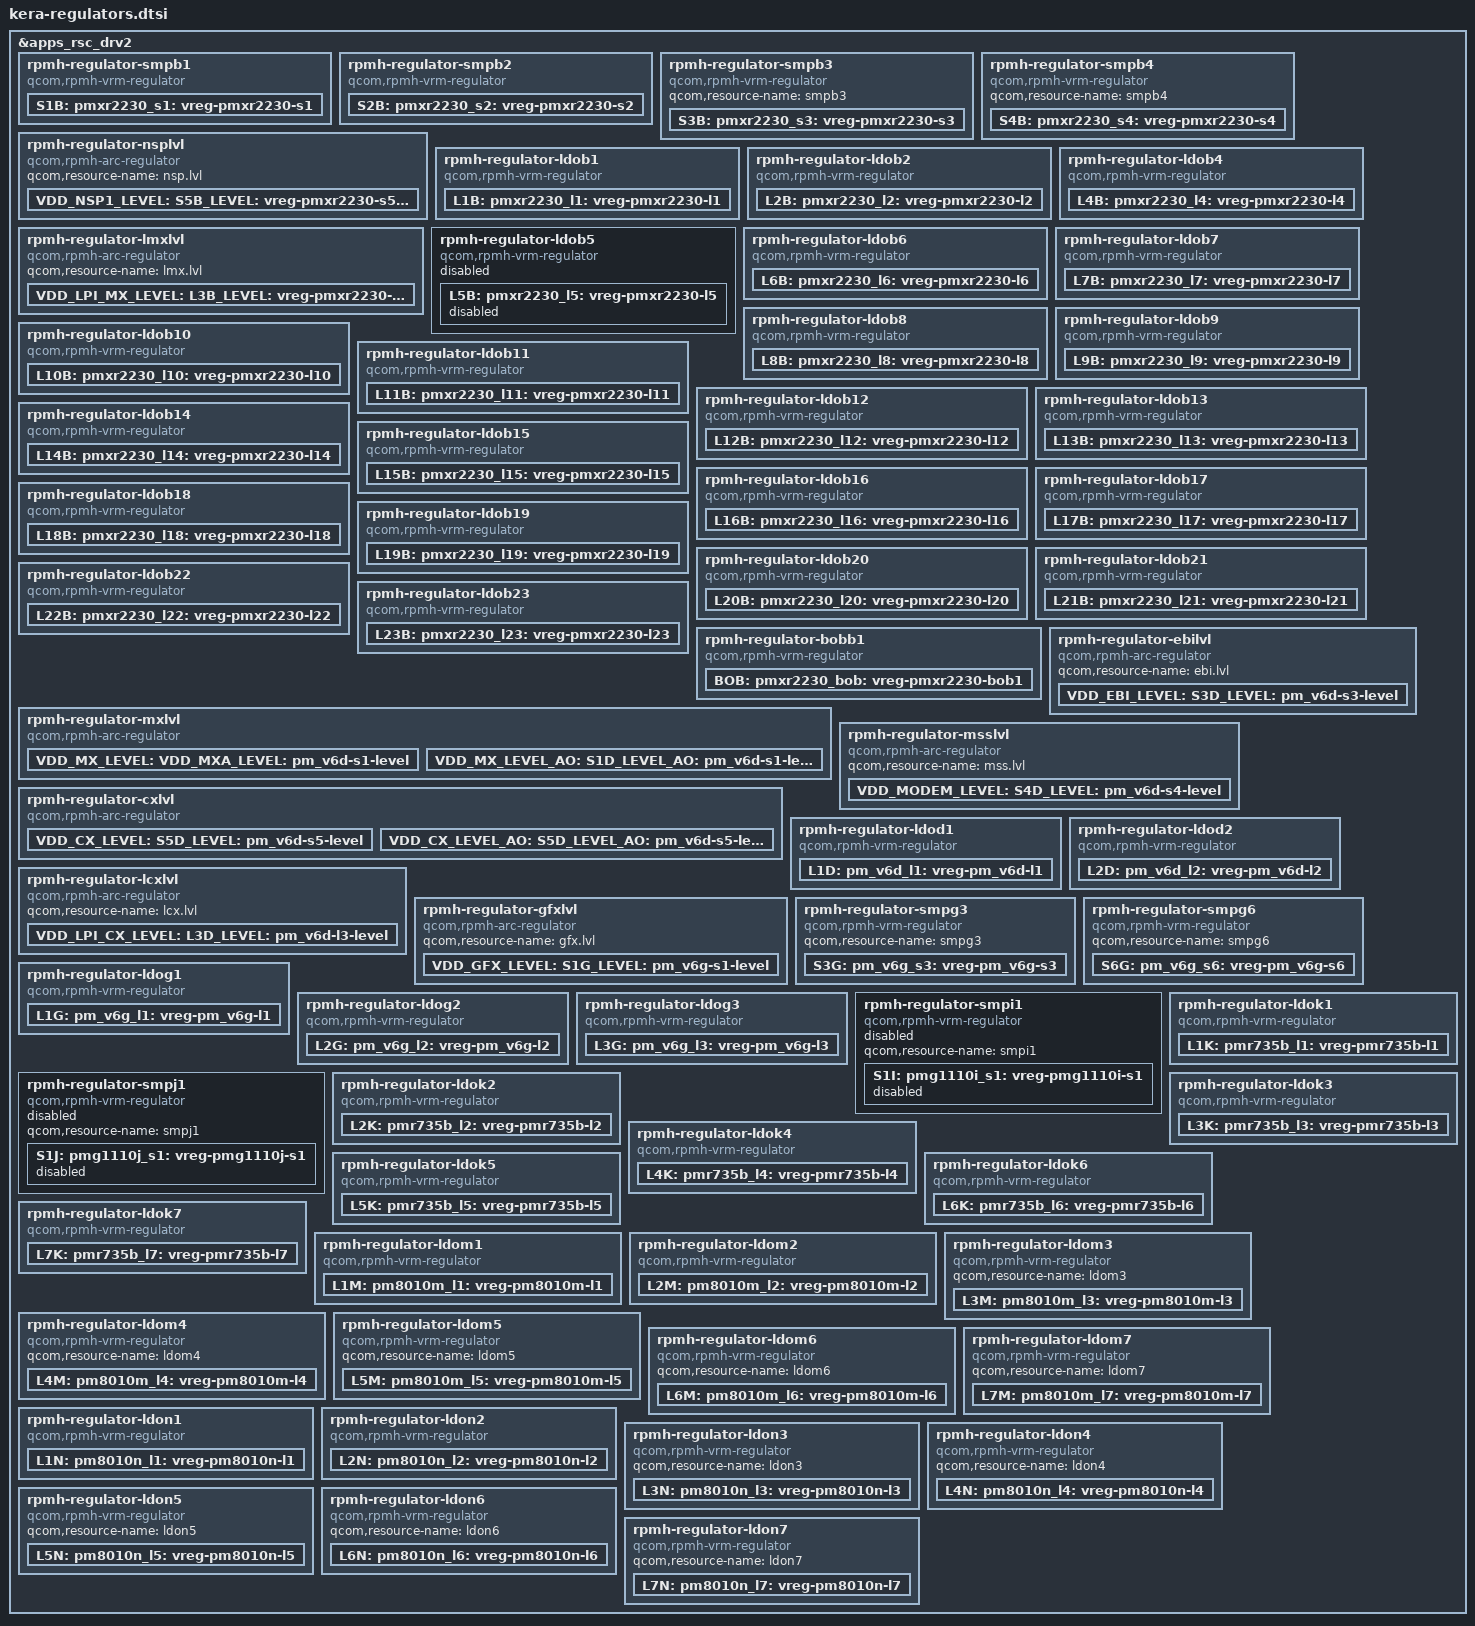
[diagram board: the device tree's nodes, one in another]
// SPDX-License-Identifier: BSD-3-Clause
/*
 * Copyright (c) 2024-2025, Qualcomm Innovation Center, Inc. All rights reserved.
 */

#include <dt-bindings/regulator/qcom,rpmh-regulator-levels.h>

&apps_rsc_drv2 {
	rpmh-regulator-smpb1 {
		compatible = "qcom,rpmh-vrm-regulator";
		qcom,resource-name = "smpb1";
		qcom,regulator-type = "pmic5-ftsmps";
		qcom,supported-modes = <RPMH_REGULATOR_MODE_RET
					RPMH_REGULATOR_MODE_HPM>;
		qcom,mode-threshold-currents = <0 200000>;

		S1B: pmxr2230_s1: vreg-pmxr2230-s1 {
			regulator-name = "pmxr2230_s1";
			qcom,set = <RPMH_REGULATOR_SET_ALL>;
			regulator-min-microvolt = <1856000>;
			regulator-max-microvolt = <2040000>;
			qcom,init-voltage = <1856000>;
			qcom,init-mode = <RPMH_REGULATOR_MODE_HPM>;
		};
	};

	rpmh-regulator-smpb2 {
		compatible = "qcom,rpmh-vrm-regulator";
		qcom,resource-name = "smpb2";
		qcom,regulator-type = "pmic5-ftsmps";
		qcom,supported-modes = <RPMH_REGULATOR_MODE_RET
					RPMH_REGULATOR_MODE_HPM>;
		qcom,mode-threshold-currents = <0 200000>;

		S2B: pmxr2230_s2: vreg-pmxr2230-s2 {
			regulator-name = "pmxr2230_s2";
			qcom,set = <RPMH_REGULATOR_SET_ALL>;
			regulator-min-microvolt = <1256000>;
			regulator-max-microvolt = <1408000>;
			qcom,init-voltage = <1256000>;
			qcom,init-mode = <RPMH_REGULATOR_MODE_HPM>;
		};
	};

	rpmh-regulator-smpb3 {
		compatible = "qcom,rpmh-vrm-regulator";
		qcom,resource-name = "smpb3";

		S3B: pmxr2230_s3: vreg-pmxr2230-s3 {
			regulator-name = "pmxr2230_s3";
			qcom,set = <RPMH_REGULATOR_SET_ALL>;
			regulator-min-microvolt = <880000>;
			regulator-max-microvolt = <1040000>;
			qcom,init-voltage = <952000>;
		};
	};

	rpmh-regulator-smpb4 {
		compatible = "qcom,rpmh-vrm-regulator";
		qcom,resource-name = "smpb4";

		S4B: pmxr2230_s4: vreg-pmxr2230-s4 {
			regulator-name = "pmxr2230_s4";
			qcom,set = <RPMH_REGULATOR_SET_ALL>;
			regulator-min-microvolt = <2156000>;
			regulator-max-microvolt = <2600000>;
			qcom,init-voltage = <2156000>;
		};
	};

	rpmh-regulator-nsplvl {
		compatible = "qcom,rpmh-arc-regulator";
		qcom,resource-name = "nsp.lvl";

		VDD_NSP1_LEVEL:
		S5B_LEVEL:
		pmxr2230_s5_level: vreg-pmxr2230-s5-level {
			regulator-name = "pmxr2230_s5_level";
			qcom,set = <RPMH_REGULATOR_SET_ALL>;
			regulator-min-microvolt =
				<RPMH_REGULATOR_LEVEL_RETENTION>;
			regulator-max-microvolt = <RPMH_REGULATOR_LEVEL_MAX>;
			qcom,init-voltage-level =
				<RPMH_REGULATOR_LEVEL_RETENTION>;
		};
	};

	rpmh-regulator-ldob1 {
		compatible = "qcom,rpmh-vrm-regulator";
		qcom,resource-name = "ldob1";
		qcom,regulator-type = "pmic5-ldo";
		qcom,supported-modes =
			<RPMH_REGULATOR_MODE_LPM
			RPMH_REGULATOR_MODE_HPM>;
		qcom,mode-threshold-currents = <0 30000>;

		L1B: pmxr2230_l1: vreg-pmxr2230-l1 {
			regulator-name = "pmxr2230_l1";
			qcom,set = <RPMH_REGULATOR_SET_ALL>;
			regulator-min-microvolt = <870000>;
			regulator-max-microvolt = <970000>;
			qcom,init-voltage = <904000>;
			qcom,init-mode = <RPMH_REGULATOR_MODE_HPM>;
		};
	};

	rpmh-regulator-ldob2 {
		compatible = "qcom,rpmh-vrm-regulator";
		qcom,resource-name = "ldob2";
		qcom,regulator-type = "pmic5-ldo";
		qcom,supported-modes =
			<RPMH_REGULATOR_MODE_LPM
			RPMH_REGULATOR_MODE_HPM>;
		qcom,mode-threshold-currents = <0 30000>;
		proxy-supply = <&L2B>;

		L2B: pmxr2230_l2: vreg-pmxr2230-l2 {
			regulator-name = "pmxr2230_l2";
			qcom,set = <RPMH_REGULATOR_SET_ALL>;
			regulator-min-microvolt = <720000>;
			regulator-max-microvolt = <950000>;
			qcom,init-voltage = <720000>;
			qcom,init-mode = <RPMH_REGULATOR_MODE_HPM>;
			qcom,proxy-consumer-enable;
			qcom,proxy-consumer-current = <98000>;
		};
	};

	rpmh-regulator-lmxlvl {
		compatible = "qcom,rpmh-arc-regulator";
		qcom,resource-name = "lmx.lvl";

		VDD_LPI_MX_LEVEL:
		L3B_LEVEL:
		pmxr2230_l3_level: vreg-pmxr2230-l3-level {
			regulator-name = "pmxr2230_l3_level";
			qcom,set = <RPMH_REGULATOR_SET_ALL>;
			regulator-min-microvolt =
				<RPMH_REGULATOR_LEVEL_RETENTION>;
			regulator-max-microvolt = <RPMH_REGULATOR_LEVEL_MAX>;
			qcom,init-voltage-level =
				<RPMH_REGULATOR_LEVEL_RETENTION>;
		};
	};

	rpmh-regulator-ldob4 {
		compatible = "qcom,rpmh-vrm-regulator";
		qcom,resource-name = "ldob4";
		qcom,regulator-type = "pmic5-ldo";
		qcom,supported-modes =
			<RPMH_REGULATOR_MODE_LPM
			RPMH_REGULATOR_MODE_HPM>;
		qcom,mode-threshold-currents = <0 30000>;
		proxy-supply = <&L4B>;

		L4B: pmxr2230_l4: vreg-pmxr2230-l4 {
			regulator-name = "pmxr2230_l4";
			qcom,set = <RPMH_REGULATOR_SET_ALL>;
			regulator-min-microvolt = <1080000>;
			regulator-max-microvolt = <1320000>;
			qcom,init-voltage = <1200000>;
			qcom,init-mode = <RPMH_REGULATOR_MODE_HPM>;
			qcom,proxy-consumer-enable;
			qcom,proxy-consumer-current = <16600>;
		};
	};

	rpmh-regulator-ldob5 {
		compatible = "qcom,rpmh-vrm-regulator";
		qcom,resource-name = "ldob5";
		qcom,regulator-type = "pmic5-ldo";
		qcom,supported-modes =
			<RPMH_REGULATOR_MODE_LPM
			RPMH_REGULATOR_MODE_HPM>;
		qcom,mode-threshold-currents = <0 30000>;
		status = "disabled";

		L5B: pmxr2230_l5: vreg-pmxr2230-l5 {
			regulator-name = "pmxr2230_l5";
			qcom,set = <RPMH_REGULATOR_SET_ALL>;
			regulator-min-microvolt = <1170000>;
			regulator-max-microvolt = <1370000>;
			qcom,init-voltage = <1200000>;
			qcom,init-mode = <RPMH_REGULATOR_MODE_HPM>;
			status = "disabled";
		};
	};

	rpmh-regulator-ldob6 {
		compatible = "qcom,rpmh-vrm-regulator";
		qcom,resource-name = "ldob6";
		qcom,regulator-type = "pmic5-ldo";
		qcom,supported-modes =
			<RPMH_REGULATOR_MODE_LPM
			RPMH_REGULATOR_MODE_HPM>;
		qcom,mode-threshold-currents = <0 30000>;

		L6B: pmxr2230_l6: vreg-pmxr2230-l6 {
			regulator-name = "pmxr2230_l6";
			qcom,set = <RPMH_REGULATOR_SET_ALL>;
			regulator-min-microvolt = <866000>;
			regulator-max-microvolt = <958000>;
			qcom,init-voltage = <912000>;
			qcom,init-mode = <RPMH_REGULATOR_MODE_HPM>;
		};
	};

	rpmh-regulator-ldob7 {
		compatible = "qcom,rpmh-vrm-regulator";
		qcom,resource-name = "ldob7";
		qcom,regulator-type = "pmic5-ldo";
		qcom,supported-modes =
			<RPMH_REGULATOR_MODE_LPM
			RPMH_REGULATOR_MODE_HPM>;
		qcom,mode-threshold-currents = <0 30000>;

		L7B: pmxr2230_l7: vreg-pmxr2230-l7 {
			regulator-name = "pmxr2230_l7";
			qcom,set = <RPMH_REGULATOR_SET_ALL>;
			regulator-min-microvolt = <1800000>;
			regulator-max-microvolt = <2000000>;
			qcom,init-voltage = <1800000>;
			qcom,init-mode = <RPMH_REGULATOR_MODE_HPM>;
		};
	};

	rpmh-regulator-ldob8 {
		compatible = "qcom,rpmh-vrm-regulator";
		qcom,resource-name = "ldob8";
		qcom,regulator-type = "pmic5-ldo";
		qcom,supported-modes =
			<RPMH_REGULATOR_MODE_LPM
			RPMH_REGULATOR_MODE_HPM>;
		qcom,mode-threshold-currents = <0 30000>;
		proxy-supply = <&L8B>;

		L8B: pmxr2230_l8: vreg-pmxr2230-l8 {
			regulator-name = "pmxr2230_l8";
			qcom,set = <RPMH_REGULATOR_SET_ALL>;
			regulator-min-microvolt = <1650000>;
			regulator-max-microvolt = <2000000>;
			qcom,init-voltage = <1800000>;
			qcom,init-mode = <RPMH_REGULATOR_MODE_HPM>;
			qcom,proxy-consumer-enable;
			qcom,proxy-consumer-current = <154000>;
		};
	};

	rpmh-regulator-ldob9 {
		compatible = "qcom,rpmh-vrm-regulator";
		qcom,resource-name = "ldob9";
		qcom,regulator-type = "pmic5-ldo";
		qcom,supported-modes =
			<RPMH_REGULATOR_MODE_LPM
			RPMH_REGULATOR_MODE_HPM>;
		qcom,mode-threshold-currents = <0 30000>;

		L9B: pmxr2230_l9: vreg-pmxr2230-l9 {
			regulator-name = "pmxr2230_l9";
			qcom,set = <RPMH_REGULATOR_SET_ALL>;
			regulator-min-microvolt = <756000>;
			regulator-max-microvolt = <816000>;
			qcom,init-voltage = <756000>;
			qcom,init-mode = <RPMH_REGULATOR_MODE_HPM>;
		};
	};

	rpmh-regulator-ldob10 {
		compatible = "qcom,rpmh-vrm-regulator";
		qcom,resource-name = "ldob10";
		qcom,regulator-type = "pmic5-ldo";
		qcom,supported-modes =
			<RPMH_REGULATOR_MODE_LPM
			RPMH_REGULATOR_MODE_HPM>;
		qcom,mode-threshold-currents = <0 30000>;

		L10B: pmxr2230_l10: vreg-pmxr2230-l10 {
			regulator-name = "pmxr2230_l10";
			qcom,set = <RPMH_REGULATOR_SET_ALL>;
			regulator-min-microvolt = <866000>;
			regulator-max-microvolt = <958000>;
			qcom,init-voltage = <866000>;
			qcom,init-mode = <RPMH_REGULATOR_MODE_HPM>;
		};
	};

	rpmh-regulator-ldob11 {
		compatible = "qcom,rpmh-vrm-regulator";
		qcom,resource-name = "ldob11";
		qcom,regulator-type = "pmic5-ldo";
		qcom,supported-modes =
			<RPMH_REGULATOR_MODE_RET
			RPMH_REGULATOR_MODE_HPM>;
		qcom,mode-threshold-currents = <0 30000>;

		L11B: pmxr2230_l11: vreg-pmxr2230-l11 {
			regulator-name = "pmxr2230_l11";
			qcom,set = <RPMH_REGULATOR_SET_ALL>;
			regulator-min-microvolt = <1800000>;
			regulator-max-microvolt = <2000000>;
			qcom,init-voltage = <1800000>;
			qcom,init-mode = <RPMH_REGULATOR_MODE_LPM>;
			regulator-always-on;
		};
	};

	rpmh-regulator-ldob12 {
		compatible = "qcom,rpmh-vrm-regulator";
		qcom,resource-name = "ldob12";
		qcom,regulator-type = "pmic5-ldo";
		qcom,supported-modes =
			<RPMH_REGULATOR_MODE_LPM
			RPMH_REGULATOR_MODE_HPM>;
		qcom,mode-threshold-currents = <0 10000>;

		L12B: pmxr2230_l12: vreg-pmxr2230-l12 {
			regulator-name = "pmxr2230_l12";
			qcom,set = <RPMH_REGULATOR_SET_ALL>;
			qcom,init-mode = <RPMH_REGULATOR_MODE_HPM>;
		};
	};

	rpmh-regulator-ldob13 {
		compatible = "qcom,rpmh-vrm-regulator";
		qcom,resource-name = "ldob13";
		qcom,regulator-type = "pmic5-ldo";
		qcom,supported-modes =
			<RPMH_REGULATOR_MODE_LPM
			RPMH_REGULATOR_MODE_HPM>;
		qcom,mode-threshold-currents = <0 10000>;

		L13B: pmxr2230_l13: vreg-pmxr2230-l13 {
			regulator-name = "pmxr2230_l13";
			qcom,set = <RPMH_REGULATOR_SET_ALL>;
			regulator-min-microvolt = <2700000>;
			regulator-max-microvolt = <3300000>;
			qcom,init-voltage = <2700000>;
			qcom,init-mode = <RPMH_REGULATOR_MODE_HPM>;
		};
	};

	rpmh-regulator-ldob14 {
		compatible = "qcom,rpmh-vrm-regulator";
		qcom,resource-name = "ldob14";
		qcom,regulator-type = "pmic5-ldo";
		qcom,supported-modes =
			<RPMH_REGULATOR_MODE_LPM
			RPMH_REGULATOR_MODE_HPM>;
		qcom,mode-threshold-currents = <0 10000>;

		L14B: pmxr2230_l14: vreg-pmxr2230-l14 {
			regulator-name = "pmxr2230_l14";
			qcom,set = <RPMH_REGULATOR_SET_ALL>;
			regulator-min-microvolt = <2650000>;
			regulator-max-microvolt = <2940000>;
			qcom,init-voltage = <2650000>;
			qcom,init-mode = <RPMH_REGULATOR_MODE_HPM>;
		};
	};

	rpmh-regulator-ldob15 {
		compatible = "qcom,rpmh-vrm-regulator";
		qcom,resource-name = "ldob15";
		qcom,regulator-type = "pmic5-ldo";
		qcom,supported-modes =
			<RPMH_REGULATOR_MODE_LPM
			RPMH_REGULATOR_MODE_HPM>;
		qcom,mode-threshold-currents = <0 10000>;

		L15B: pmxr2230_l15: vreg-pmxr2230-l15 {
			regulator-name = "pmxr2230_l15";
			qcom,set = <RPMH_REGULATOR_SET_ALL>;
			regulator-min-microvolt = <1620000>;
			regulator-max-microvolt = <3300000>;
			qcom,init-voltage = <1620000>;
			qcom,init-mode = <RPMH_REGULATOR_MODE_HPM>;
		};
	};

	rpmh-regulator-ldob16 {
		compatible = "qcom,rpmh-vrm-regulator";
		qcom,resource-name = "ldob16";
		qcom,regulator-type = "pmic5-ldo";
		qcom,supported-modes =
			<RPMH_REGULATOR_MODE_LPM
			RPMH_REGULATOR_MODE_HPM>;
		qcom,mode-threshold-currents = <0 10000>;

		L16B: pmxr2230_l16: vreg-pmxr2230-l16 {
			regulator-name = "pmxr2230_l16";
			qcom,set = <RPMH_REGULATOR_SET_ALL>;
			regulator-min-microvolt = <2900000>;
			regulator-max-microvolt = <3544000>;
			qcom,init-voltage = <2900000>;
			qcom,init-mode = <RPMH_REGULATOR_MODE_HPM>;
		};
	};

	rpmh-regulator-ldob17 {
		compatible = "qcom,rpmh-vrm-regulator";
		qcom,resource-name = "ldob17";
		qcom,regulator-type = "pmic5-ldo";
		qcom,supported-modes =
			<RPMH_REGULATOR_MODE_LPM
			RPMH_REGULATOR_MODE_HPM>;
		qcom,mode-threshold-currents = <0 10000>;

		L17B: pmxr2230_l17: vreg-pmxr2230-l17 {
			regulator-name = "pmxr2230_l17";
			qcom,set = <RPMH_REGULATOR_SET_ALL>;
			regulator-min-microvolt = <2700000>;
			regulator-max-microvolt = <3544000>;
			qcom,init-voltage = <3104000>;
			qcom,init-mode = <RPMH_REGULATOR_MODE_HPM>;
		};
	};

	rpmh-regulator-ldob18 {
		compatible = "qcom,rpmh-vrm-regulator";
		qcom,resource-name = "ldob18";
		qcom,regulator-type = "pmic5-ldo";
		qcom,supported-modes =
			<RPMH_REGULATOR_MODE_LPM
			RPMH_REGULATOR_MODE_HPM>;
		qcom,mode-threshold-currents = <0 10000>;

		L18B: pmxr2230_l18: vreg-pmxr2230-l18 {
			regulator-name = "pmxr2230_l18";
			qcom,set = <RPMH_REGULATOR_SET_ALL>;
			regulator-min-microvolt = <1600000>;
			regulator-max-microvolt = <3544000>;
			qcom,init-voltage = <1600000>;
			qcom,init-mode = <RPMH_REGULATOR_MODE_HPM>;
		};
	};

	rpmh-regulator-ldob19 {
		compatible = "qcom,rpmh-vrm-regulator";
		qcom,resource-name = "ldob19";
		qcom,regulator-type = "pmic5-ldo";
		qcom,supported-modes =
			<RPMH_REGULATOR_MODE_LPM
			RPMH_REGULATOR_MODE_HPM>;
		qcom,mode-threshold-currents = <0 10000>;
		proxy-supply = <&L19B>;

		L19B: pmxr2230_l19: vreg-pmxr2230-l19 {
			regulator-name = "pmxr2230_l19";
			qcom,set = <RPMH_REGULATOR_SET_ALL>;
			regulator-min-microvolt = <2600000>;
			regulator-max-microvolt = <3544000>;
			qcom,init-voltage = <2600000>;
			qcom,init-mode = <RPMH_REGULATOR_MODE_HPM>;
			qcom,proxy-consumer-enable;
			qcom,proxy-consumer-current = <10000>;
		};
	};

	rpmh-regulator-ldob20 {
		compatible = "qcom,rpmh-vrm-regulator";
		qcom,resource-name = "ldob20";
		qcom,regulator-type = "pmic5-ldo";
		qcom,supported-modes =
			<RPMH_REGULATOR_MODE_LPM
			RPMH_REGULATOR_MODE_HPM>;
		qcom,mode-threshold-currents = <0 10000>;

		L20B: pmxr2230_l20: vreg-pmxr2230-l20 {
			regulator-name = "pmxr2230_l20";
			qcom,set = <RPMH_REGULATOR_SET_ALL>;
			regulator-min-microvolt = <1504000>;
			regulator-max-microvolt = <3544000>;
			qcom,init-voltage = <1504000>;
			qcom,init-mode = <RPMH_REGULATOR_MODE_HPM>;
		};
	};

	rpmh-regulator-ldob21 {
		compatible = "qcom,rpmh-vrm-regulator";
		qcom,resource-name = "ldob21";
		qcom,regulator-type = "pmic5-ldo";
		qcom,supported-modes =
			<RPMH_REGULATOR_MODE_LPM
			RPMH_REGULATOR_MODE_HPM>;
		qcom,mode-threshold-currents = <0 10000>;

		L21B: pmxr2230_l21: vreg-pmxr2230-l21 {
			regulator-name = "pmxr2230_l21";
			qcom,set = <RPMH_REGULATOR_SET_ALL>;
			regulator-min-microvolt = <1504000>;
			regulator-max-microvolt = <3544000>;
			qcom,init-voltage = <1504000>;
			qcom,init-mode = <RPMH_REGULATOR_MODE_HPM>;
		};
	};

	rpmh-regulator-ldob22 {
		compatible = "qcom,rpmh-vrm-regulator";
		qcom,resource-name = "ldob22";
		qcom,regulator-type = "pmic5-ldo";
		qcom,supported-modes =
			<RPMH_REGULATOR_MODE_LPM
			RPMH_REGULATOR_MODE_HPM>;
		qcom,mode-threshold-currents = <0 10000>;

		L22B: pmxr2230_l22: vreg-pmxr2230-l22 {
			regulator-name = "pmxr2230_l22";
			qcom,set = <RPMH_REGULATOR_SET_ALL>;
			regulator-min-microvolt = <2700000>;
			regulator-max-microvolt = <3400000>;
			qcom,init-voltage = <2700000>;
			qcom,init-mode = <RPMH_REGULATOR_MODE_HPM>;
		};
	};

	rpmh-regulator-ldob23 {
		compatible = "qcom,rpmh-vrm-regulator";
		qcom,resource-name = "ldob23";
		qcom,regulator-type = "pmic5-ldo";
		qcom,supported-modes =
			<RPMH_REGULATOR_MODE_LPM
			RPMH_REGULATOR_MODE_HPM>;
		qcom,mode-threshold-currents = <0 10000>;

		L23B: pmxr2230_l23: vreg-pmxr2230-l23 {
			regulator-name = "pmxr2230_l23";
			qcom,set = <RPMH_REGULATOR_SET_ALL>;
			regulator-min-microvolt = <1650000>;
			regulator-max-microvolt = <3544000>;
			qcom,init-voltage = <1650000>;
			qcom,init-mode = <RPMH_REGULATOR_MODE_HPM>;
		};
	};

	rpmh-regulator-bobb1 {
		compatible = "qcom,rpmh-vrm-regulator";
		qcom,resource-name = "bobb1";
		qcom,regulator-type = "pmic5-bob";
		qcom,supported-modes =
			<RPMH_REGULATOR_MODE_PASS
			RPMH_REGULATOR_MODE_LPM
			RPMH_REGULATOR_MODE_HPM>;
		qcom,mode-threshold-currents = <0 1000000 2000000>;
		BOB:
		pmxr2230_bob: vreg-pmxr2230-bob1 {
			regulator-name = "pmxr2230_bob";
			qcom,set = <RPMH_REGULATOR_SET_ALL>;
			regulator-min-microvolt = <3008000>;
			regulator-max-microvolt = <3960000>;
			qcom,init-voltage = <3296000>;
		};
	};

	rpmh-regulator-mxlvl {
		compatible = "qcom,rpmh-arc-regulator";
		qcom,resource-name = "mx.lvl";
		proxy-supply = <&VDD_MXA_LEVEL>;

		VDD_MX_LEVEL:
		VDD_MXA_LEVEL:
		S1D_LEVEL:
		pm_v6d_s1_level: pm_v6d-s1-level {
			regulator-name = "pm_v6d_s1_level";
			qcom,set = <RPMH_REGULATOR_SET_ALL>;
			regulator-min-microvolt =
				<RPMH_REGULATOR_LEVEL_RETENTION>;
			regulator-max-microvolt = <RPMH_REGULATOR_LEVEL_MAX>;
			qcom,init-voltage-level =
				<RPMH_REGULATOR_LEVEL_TURBO>;
			qcom,proxy-consumer-enable;
			qcom,proxy-consumer-voltage =
				<RPMH_REGULATOR_LEVEL_TURBO
				RPMH_REGULATOR_LEVEL_MAX>;
		};

		VDD_MX_LEVEL_AO:
		S1D_LEVEL_AO:
		pm_v6d_s1_level_ao: pm_v6d-s1-level-ao {
			regulator-name = "pm_v6d_s1_level_ao";
			qcom,set = <RPMH_REGULATOR_SET_ACTIVE>;
			regulator-min-microvolt =
				<RPMH_REGULATOR_LEVEL_RETENTION>;
			regulator-max-microvolt = <RPMH_REGULATOR_LEVEL_MAX>;
			qcom,init-voltage-level =
				<RPMH_REGULATOR_LEVEL_RETENTION>;
		};
	};

	rpmh-regulator-ebilvl {
		compatible = "qcom,rpmh-arc-regulator";
		qcom,resource-name = "ebi.lvl";

		VDD_EBI_LEVEL:
		S3D_LEVEL:
		pm_v6d_s3_level: pm_v6d-s3-level {
			regulator-name = "pm_v6d_s3_level";
			qcom,set = <RPMH_REGULATOR_SET_ALL>;
			regulator-min-microvolt =
				<RPMH_REGULATOR_LEVEL_RETENTION>;
			regulator-max-microvolt = <RPMH_REGULATOR_LEVEL_MAX>;
			qcom,init-voltage-level =
				<RPMH_REGULATOR_LEVEL_RETENTION>;
		};
	};

	rpmh-regulator-msslvl {
		compatible = "qcom,rpmh-arc-regulator";
		qcom,resource-name = "mss.lvl";

		VDD_MODEM_LEVEL:
		S4D_LEVEL:
		pm_v6d_s4_level: pm_v6d-s4-level {
			regulator-name = "pm_v6d_s4_level";
			qcom,set = <RPMH_REGULATOR_SET_ALL>;
			regulator-min-microvolt =
				<RPMH_REGULATOR_LEVEL_RETENTION>;
			regulator-max-microvolt = <RPMH_REGULATOR_LEVEL_MAX>;
			qcom,init-voltage-level =
				<RPMH_REGULATOR_LEVEL_RETENTION>;
		};
	};

	rpmh-regulator-cxlvl {
		compatible = "qcom,rpmh-arc-regulator";
		qcom,resource-name = "cx.lvl";
		proxy-supply = <&VDD_CX_LEVEL>;

		VDD_CX_LEVEL:
		S5D_LEVEL:
		pm_v6d_s5_level: pm_v6d-s5-level {
			regulator-name = "pm_v6d_s5_level";
			qcom,set = <RPMH_REGULATOR_SET_ALL>;
			regulator-min-microvolt =
				<RPMH_REGULATOR_LEVEL_RETENTION>;
			regulator-max-microvolt = <RPMH_REGULATOR_LEVEL_MAX>;
			qcom,init-voltage-level =
				<RPMH_REGULATOR_LEVEL_TURBO>;
			qcom,proxy-consumer-enable;
			qcom,proxy-consumer-voltage =
					<RPMH_REGULATOR_LEVEL_TURBO
					RPMH_REGULATOR_LEVEL_MAX>;
		};

		VDD_CX_LEVEL_AO:
		S5D_LEVEL_AO:
		pm_v6d_s5_level_ao: pm_v6d-s5-level-ao {
			regulator-name = "pm_v6d_s5_level_ao";
			qcom,set = <RPMH_REGULATOR_SET_ACTIVE>;
			regulator-min-microvolt =
				<RPMH_REGULATOR_LEVEL_RETENTION>;
			regulator-max-microvolt = <RPMH_REGULATOR_LEVEL_MAX>;
			qcom,init-voltage-level =
				<RPMH_REGULATOR_LEVEL_RETENTION>;
		};
	};

	rpmh-regulator-ldod1 {
		compatible = "qcom,rpmh-vrm-regulator";
		qcom,resource-name = "ldod1";
		qcom,regulator-type = "pmic5-ldo";
		qcom,supported-modes =
			<RPMH_REGULATOR_MODE_LPM
			RPMH_REGULATOR_MODE_HPM>;
		qcom,mode-threshold-currents = <0 30000>;

		L1D: pm_v6d_l1: vreg-pm_v6d-l1 {
			regulator-name = "pm_v6d_l1";
			qcom,set = <RPMH_REGULATOR_SET_ALL>;
			qcom,init-mode = <RPMH_REGULATOR_MODE_HPM>;
		};
	};

	rpmh-regulator-ldod2 {
		compatible = "qcom,rpmh-vrm-regulator";
		qcom,resource-name = "ldod2";
		qcom,regulator-type = "pmic5-ldo";
		qcom,supported-modes =
			<RPMH_REGULATOR_MODE_LPM
			RPMH_REGULATOR_MODE_HPM>;
		qcom,mode-threshold-currents = <0 30000>;

		L2D: pm_v6d_l2: vreg-pm_v6d-l2 {
			regulator-name = "pm_v6d_l2";
			qcom,set = <RPMH_REGULATOR_SET_ALL>;
			regulator-min-microvolt = <556000>;
			regulator-max-microvolt = <868000>;
			qcom,init-voltage = <556000>;
			qcom,init-mode = <RPMH_REGULATOR_MODE_HPM>;
		};
	};

	rpmh-regulator-lcxlvl {
		compatible = "qcom,rpmh-arc-regulator";
		qcom,resource-name = "lcx.lvl";

		VDD_LPI_CX_LEVEL:
		L3D_LEVEL:
		pm_v6d_l3_level: pm_v6d-l3-level {
			regulator-name = "pm_v6d_l3_level";
			qcom,set = <RPMH_REGULATOR_SET_ALL>;
			regulator-min-microvolt =
				<RPMH_REGULATOR_LEVEL_RETENTION>;
			regulator-max-microvolt = <RPMH_REGULATOR_LEVEL_MAX>;
			qcom,init-voltage-level =
				<RPMH_REGULATOR_LEVEL_RETENTION>;
		};
	};

	rpmh-regulator-gfxlvl {
		compatible = "qcom,rpmh-arc-regulator";
		qcom,resource-name = "gfx.lvl";

		VDD_GFX_LEVEL:
		S1G_LEVEL:
		pm_v6g_s1_level: pm_v6g-s1-level {
			regulator-name = "pm_v6g_s1_level";
			qcom,set = <RPMH_REGULATOR_SET_ALL>;
			regulator-min-microvolt =
				<RPMH_REGULATOR_LEVEL_RETENTION>;
			regulator-max-microvolt = <RPMH_REGULATOR_LEVEL_MAX>;
			qcom,init-voltage-level =
				<RPMH_REGULATOR_LEVEL_RETENTION>;
		};
	};

	rpmh-regulator-smpg3 {
		compatible = "qcom,rpmh-vrm-regulator";
		qcom,resource-name = "smpg3";

		S3G: pm_v6g_s3: vreg-pm_v6g-s3 {
			regulator-name = "pm_v6g_s3";
			qcom,set = <RPMH_REGULATOR_SET_ALL>;
			regulator-min-microvolt = <1010000>;
			regulator-max-microvolt = <1170000>;
			qcom,init-voltage = <1010000>;
		};
	};

	rpmh-regulator-smpg6 {
		compatible = "qcom,rpmh-vrm-regulator";
		qcom,resource-name = "smpg6";

		S6G: pm_v6g_s6: vreg-pm_v6g-s6 {
			regulator-name = "pm_v6g_s6";
			qcom,set = <RPMH_REGULATOR_SET_ALL>;
			regulator-min-microvolt = <300000>;
			regulator-max-microvolt = <650000>;
			qcom,init-voltage = <300000>;
		};
	};

	rpmh-regulator-ldog1 {
		compatible = "qcom,rpmh-vrm-regulator";
		qcom,resource-name = "ldog1";
		qcom,regulator-type = "pmic5-ldo";
		qcom,supported-modes =
			<RPMH_REGULATOR_MODE_LPM
			RPMH_REGULATOR_MODE_HPM>;
		qcom,mode-threshold-currents = <0 30000>;
		proxy-supply = <&L1G>;

		L1G: pm_v6g_l1: vreg-pm_v6g-l1 {
			regulator-name = "pm_v6g_l1";
			qcom,set = <RPMH_REGULATOR_SET_ALL>;
			regulator-min-microvolt = <1150000>;
			regulator-max-microvolt = <1250000>;
			qcom,init-voltage = <1150000>;
			qcom,init-mode = <RPMH_REGULATOR_MODE_HPM>;
			qcom,proxy-consumer-enable;
			qcom,proxy-consumer-current = <220000>;
		};
	};

	rpmh-regulator-ldog2 {
		compatible = "qcom,rpmh-vrm-regulator";
		qcom,resource-name = "ldog2";
		qcom,regulator-type = "pmic5-ldo";
		qcom,supported-modes =
			<RPMH_REGULATOR_MODE_LPM
			RPMH_REGULATOR_MODE_HPM>;
		qcom,mode-threshold-currents = <0 30000>;

		L2G: pm_v6g_l2: vreg-pm_v6g-l2 {
			regulator-name = "pm_v6g_l2";
			qcom,set = <RPMH_REGULATOR_SET_ALL>;
			regulator-min-microvolt = <1080000>;
			regulator-max-microvolt = <2000000>;
			qcom,init-voltage = <1080000>;
			qcom,init-mode = <RPMH_REGULATOR_MODE_HPM>;
		};
	};

	rpmh-regulator-ldog3 {
		compatible = "qcom,rpmh-vrm-regulator";
		qcom,resource-name = "ldog3";
		qcom,regulator-type = "pmic5-ldo";
		qcom,supported-modes =
			<RPMH_REGULATOR_MODE_LPM
			RPMH_REGULATOR_MODE_HPM>;
		qcom,mode-threshold-currents = <0 30000>;

		L3G: pm_v6g_l3: vreg-pm_v6g-l3 {
			regulator-name = "pm_v6g_l3";
			qcom,set = <RPMH_REGULATOR_SET_ALL>;
			regulator-min-microvolt = <1200000>;
			regulator-max-microvolt = <1304000>;
			qcom,init-voltage = <1200000>;
			qcom,init-mode = <RPMH_REGULATOR_MODE_HPM>;
		};
	};

	rpmh-regulator-smpi1 {
		compatible = "qcom,rpmh-vrm-regulator";
		qcom,resource-name = "smpi1";
		status = "disabled";

		S1I: pmg1110i_s1: vreg-pmg1110i-s1 {
			regulator-name = "pmg1110i_s1";
			qcom,set = <RPMH_REGULATOR_SET_ALL>;
			regulator-min-microvolt = <870000>;
			regulator-max-microvolt = <970000>;
			qcom,init-voltage = <904000>;
			status = "disabled";
		};
	};

	rpmh-regulator-smpj1 {
		compatible = "qcom,rpmh-vrm-regulator";
		qcom,resource-name = "smpj1";
		status = "disabled";

		S1J: pmg1110j_s1: vreg-pmg1110j-s1 {
			regulator-name = "pmg1110j_s1";
			qcom,set = <RPMH_REGULATOR_SET_ALL>;
			regulator-min-microvolt = <556000>;
			regulator-max-microvolt = <816000>;
			qcom,init-voltage = <556000>;
			status = "disabled";
		};
	};

	rpmh-regulator-ldok1 {
		compatible = "qcom,rpmh-vrm-regulator";
		qcom,resource-name = "ldok1";
		qcom,regulator-type = "pmic5-ldo";
		qcom,supported-modes =
			<RPMH_REGULATOR_MODE_LPM
			RPMH_REGULATOR_MODE_HPM>;
		qcom,mode-threshold-currents = <0 30000>;

		L1K: pmr735b_l1: vreg-pmr735b-l1 {
			regulator-name = "pmr735b_l1";
			qcom,set = <RPMH_REGULATOR_SET_ALL>;
			regulator-min-microvolt = <806000>;
			regulator-max-microvolt = <912000>;
			qcom,init-voltage = <806000>;
			qcom,init-mode = <RPMH_REGULATOR_MODE_HPM>;
		};
	};

	rpmh-regulator-ldok2 {
		compatible = "qcom,rpmh-vrm-regulator";
		qcom,resource-name = "ldok2";
		qcom,regulator-type = "pmic5-ldo";
		qcom,supported-modes =
			<RPMH_REGULATOR_MODE_LPM
			RPMH_REGULATOR_MODE_HPM>;
		qcom,mode-threshold-currents = <0 30000>;

		L2K: pmr735b_l2: vreg-pmr735b-l2 {
			regulator-name = "pmr735b_l2";
			qcom,set = <RPMH_REGULATOR_SET_ALL>;
			regulator-min-microvolt = <920000>;
			regulator-max-microvolt = <969000>;
			qcom,init-voltage = <920000>;
			qcom,init-mode = <RPMH_REGULATOR_MODE_HPM>;
		};
	};

	rpmh-regulator-ldok3 {
		compatible = "qcom,rpmh-vrm-regulator";
		qcom,resource-name = "ldok3";
		qcom,regulator-type = "pmic5-ldo";
		qcom,supported-modes =
			<RPMH_REGULATOR_MODE_LPM
			RPMH_REGULATOR_MODE_HPM>;
		qcom,mode-threshold-currents = <0 30000>;

		L3K: pmr735b_l3: vreg-pmr735b-l3 {
			regulator-name = "pmr735b_l3";
			qcom,set = <RPMH_REGULATOR_SET_ALL>;
			regulator-min-microvolt = <1080000>;
			regulator-max-microvolt = <1350000>;
			qcom,init-voltage = <1080000>;
			qcom,init-mode = <RPMH_REGULATOR_MODE_HPM>;
		};
	};

	rpmh-regulator-ldok4 {
		compatible = "qcom,rpmh-vrm-regulator";
		qcom,resource-name = "ldok4";
		qcom,regulator-type = "pmic5-ldo";
		qcom,supported-modes =
			<RPMH_REGULATOR_MODE_LPM
			RPMH_REGULATOR_MODE_HPM>;
		qcom,mode-threshold-currents = <0 10000>;

		L4K: pmr735b_l4: vreg-pmr735b-l4 {
			regulator-name = "pmr735b_l4";
			qcom,set = <RPMH_REGULATOR_SET_ALL>;
			regulator-min-microvolt = <960000>;
			regulator-max-microvolt = <1200000>;
			qcom,init-voltage = <960000>;
			qcom,init-mode = <RPMH_REGULATOR_MODE_HPM>;
		};
	};

	rpmh-regulator-ldok5 {
		compatible = "qcom,rpmh-vrm-regulator";
		qcom,resource-name = "ldok5";
		qcom,regulator-type = "pmic5-ldo";
		qcom,supported-modes =
			<RPMH_REGULATOR_MODE_LPM
			RPMH_REGULATOR_MODE_HPM>;
		qcom,mode-threshold-currents = <0 30000>;

		L5K: pmr735b_l5: vreg-pmr735b-l5 {
			regulator-name = "pmr735b_l5";
			qcom,set = <RPMH_REGULATOR_SET_ALL>;
			regulator-min-microvolt = <866000>;
			regulator-max-microvolt = <931000>;
			qcom,init-voltage = <866000>;
			qcom,init-mode = <RPMH_REGULATOR_MODE_HPM>;
		};
	};

	rpmh-regulator-ldok6 {
		compatible = "qcom,rpmh-vrm-regulator";
		qcom,resource-name = "ldok6";
		qcom,regulator-type = "pmic5-ldo";
		qcom,supported-modes =
			<RPMH_REGULATOR_MODE_LPM
			RPMH_REGULATOR_MODE_HPM>;
		qcom,mode-threshold-currents = <0 30000>;

		L6K: pmr735b_l6: vreg-pmr735b-l6 {
			regulator-name = "pmr735b_l6";
			qcom,set = <RPMH_REGULATOR_SET_ALL>;
			regulator-min-microvolt = <1100000>;
			regulator-max-microvolt = <2000000>;
			qcom,init-voltage = <1100000>;
			qcom,init-mode = <RPMH_REGULATOR_MODE_HPM>;
		};
	};

	rpmh-regulator-ldok7 {
		compatible = "qcom,rpmh-vrm-regulator";
		qcom,resource-name = "ldok7";
		qcom,regulator-type = "pmic5-ldo";
		qcom,supported-modes =
			<RPMH_REGULATOR_MODE_LPM
			RPMH_REGULATOR_MODE_HPM>;
		qcom,mode-threshold-currents = <0 30000>;

		L7K: pmr735b_l7: vreg-pmr735b-l7 {
			regulator-name = "pmr735b_l7";
			qcom,set = <RPMH_REGULATOR_SET_ALL>;
			regulator-min-microvolt = <720000>;
			regulator-max-microvolt = <950000>;
			qcom,init-voltage = <880000>;
			qcom,init-mode = <RPMH_REGULATOR_MODE_HPM>;
		};
	};

	rpmh-regulator-ldom1 {
		compatible = "qcom,rpmh-vrm-regulator";
		qcom,resource-name = "ldom1";
		qcom,regulator-type = "pmic5-ldo";
		qcom,supported-modes =
			<RPMH_REGULATOR_MODE_LPM
			RPMH_REGULATOR_MODE_HPM>;
		qcom,mode-threshold-currents = <0 30000>;

		L1M: pm8010m_l1: vreg-pm8010m-l1 {
			regulator-name = "pm8010m_l1";
			qcom,set = <RPMH_REGULATOR_SET_ALL>;
			regulator-min-microvolt = <1000000>;
			regulator-max-microvolt = <1200000>;
			qcom,init-voltage = <1000000>;
			qcom,init-mode = <RPMH_REGULATOR_MODE_HPM>;
		};
	};

	rpmh-regulator-ldom2 {
		compatible = "qcom,rpmh-vrm-regulator";
		qcom,resource-name = "ldom2";
		qcom,regulator-type = "pmic5-ldo";
		qcom,supported-modes =
			<RPMH_REGULATOR_MODE_LPM
			RPMH_REGULATOR_MODE_HPM>;
		qcom,mode-threshold-currents = <0 30000>;

		L2M: pm8010m_l2: vreg-pm8010m-l2 {
			regulator-name = "pm8010m_l2";
			qcom,set = <RPMH_REGULATOR_SET_ALL>;
			regulator-min-microvolt = <950000>;
			regulator-max-microvolt = <1150000>;
			qcom,init-voltage = <950000>;
			qcom,init-mode = <RPMH_REGULATOR_MODE_HPM>;
		};
	};

	rpmh-regulator-ldom3 {
		compatible = "qcom,rpmh-vrm-regulator";
		qcom,resource-name = "ldom3";

		L3M: pm8010m_l3: vreg-pm8010m-l3 {
			regulator-name = "pm8010m_l3";
			qcom,set = <RPMH_REGULATOR_SET_ALL>;
			regulator-min-microvolt = <2700000>;
			regulator-max-microvolt = <2900000>;
			qcom,init-voltage = <2700000>;
		};
	};

	rpmh-regulator-ldom4 {
		compatible = "qcom,rpmh-vrm-regulator";
		qcom,resource-name = "ldom4";

		L4M: pm8010m_l4: vreg-pm8010m-l4 {
			regulator-name = "pm8010m_l4";
			qcom,set = <RPMH_REGULATOR_SET_ALL>;
			regulator-min-microvolt = <2700000>;
			regulator-max-microvolt = <2900000>;
			qcom,init-voltage = <2700000>;
		};
	};

	rpmh-regulator-ldom5 {
		compatible = "qcom,rpmh-vrm-regulator";
		qcom,resource-name = "ldom5";

		L5M: pm8010m_l5: vreg-pm8010m-l5 {
			regulator-name = "pm8010m_l5";
			qcom,set = <RPMH_REGULATOR_SET_ALL>;
			regulator-min-microvolt = <1100000>;
			regulator-max-microvolt = <1300000>;
			qcom,init-voltage = <1504000>;
		};
	};

	rpmh-regulator-ldom6 {
		compatible = "qcom,rpmh-vrm-regulator";
		qcom,resource-name = "ldom6";

		L6M: pm8010m_l6: vreg-pm8010m-l6 {
			regulator-name = "pm8010m_l6";
			qcom,set = <RPMH_REGULATOR_SET_ALL>;
			regulator-min-microvolt = <2700000>;
			regulator-max-microvolt = <2900000>;
			qcom,init-voltage = <2700000>;
		};
	};

	rpmh-regulator-ldom7 {
		compatible = "qcom,rpmh-vrm-regulator";
		qcom,resource-name = "ldom7";

		L7M: pm8010m_l7: vreg-pm8010m-l7 {
			regulator-name = "pm8010m_l7";
			qcom,set = <RPMH_REGULATOR_SET_ALL>;
			regulator-min-microvolt = <2700000>;
			regulator-max-microvolt = <3000000>;
			qcom,init-voltage = <2700000>;
		};
	};

	rpmh-regulator-ldon1 {
		compatible = "qcom,rpmh-vrm-regulator";
		qcom,resource-name = "ldon1";
		qcom,regulator-type = "pmic5-ldo";
		qcom,supported-modes =
			<RPMH_REGULATOR_MODE_LPM
			RPMH_REGULATOR_MODE_HPM>;
		qcom,mode-threshold-currents = <0 30000>;

		L1N: pm8010n_l1: vreg-pm8010n-l1 {
			regulator-name = "pm8010n_l1";
			qcom,set = <RPMH_REGULATOR_SET_ALL>;
			regulator-min-microvolt = <1050000>;
			regulator-max-microvolt = <1200000>;
			qcom,init-voltage = <1050000>;
			qcom,init-mode = <RPMH_REGULATOR_MODE_HPM>;
		};
	};

	rpmh-regulator-ldon2 {
		compatible = "qcom,rpmh-vrm-regulator";
		qcom,resource-name = "ldon2";
		qcom,regulator-type = "pmic5-ldo";
		qcom,supported-modes =
			<RPMH_REGULATOR_MODE_LPM
			RPMH_REGULATOR_MODE_HPM>;
		qcom,mode-threshold-currents = <0 30000>;

		L2N: pm8010n_l2: vreg-pm8010n-l2 {
			regulator-name = "pm8010n_l2";
			qcom,set = <RPMH_REGULATOR_SET_ALL>;
			regulator-min-microvolt = <950000>;
			regulator-max-microvolt = <1150000>;
			qcom,init-voltage = <950000>;
			qcom,init-mode = <RPMH_REGULATOR_MODE_HPM>;
		};
	};

	rpmh-regulator-ldon3 {
		compatible = "qcom,rpmh-vrm-regulator";
		qcom,resource-name = "ldon3";

		L3N: pm8010n_l3: vreg-pm8010n-l3 {
			regulator-name = "pm8010n_l3";
			qcom,set = <RPMH_REGULATOR_SET_ALL>;
			regulator-min-microvolt = <1792000>;
			regulator-max-microvolt = <1900000>;
			qcom,init-voltage = <1792000>;
		};
	};

	rpmh-regulator-ldon4 {
		compatible = "qcom,rpmh-vrm-regulator";
		qcom,resource-name = "ldon4";

		L4N: pm8010n_l4: vreg-pm8010n-l4 {
			regulator-name = "pm8010n_l4";
			qcom,set = <RPMH_REGULATOR_SET_ALL>;
			regulator-min-microvolt = <1792000>;
			regulator-max-microvolt = <1900000>;
			qcom,init-voltage = <1792000>;
		};
	};

	rpmh-regulator-ldon5 {
		compatible = "qcom,rpmh-vrm-regulator";
		qcom,resource-name = "ldon5";

		L5N: pm8010n_l5: vreg-pm8010n-l5 {
			regulator-name = "pm8010n_l5";
			qcom,set = <RPMH_REGULATOR_SET_ALL>;
			regulator-min-microvolt = <1620000>;
			regulator-max-microvolt = <1980000>;
			qcom,init-voltage = <1620000>;
		};
	};

	rpmh-regulator-ldon6 {
		compatible = "qcom,rpmh-vrm-regulator";
		qcom,resource-name = "ldon6";

		L6N: pm8010n_l6: vreg-pm8010n-l6 {
			regulator-name = "pm8010n_l6";
			qcom,set = <RPMH_REGULATOR_SET_ALL>;
			regulator-min-microvolt = <2700000>;
			regulator-max-microvolt = <2900000>;
			qcom,init-voltage = <2700000>;
		};
	};

	rpmh-regulator-ldon7 {
		compatible = "qcom,rpmh-vrm-regulator";
		qcom,resource-name = "ldon7";

		L7N: pm8010n_l7: vreg-pm8010n-l7 {
			regulator-name = "pm8010n_l7";
			qcom,set = <RPMH_REGULATOR_SET_ALL>;
			regulator-min-microvolt = <3130000>;
			regulator-max-microvolt = <3470000>;
			qcom,init-voltage = <3130000>;
		};
	};

};
